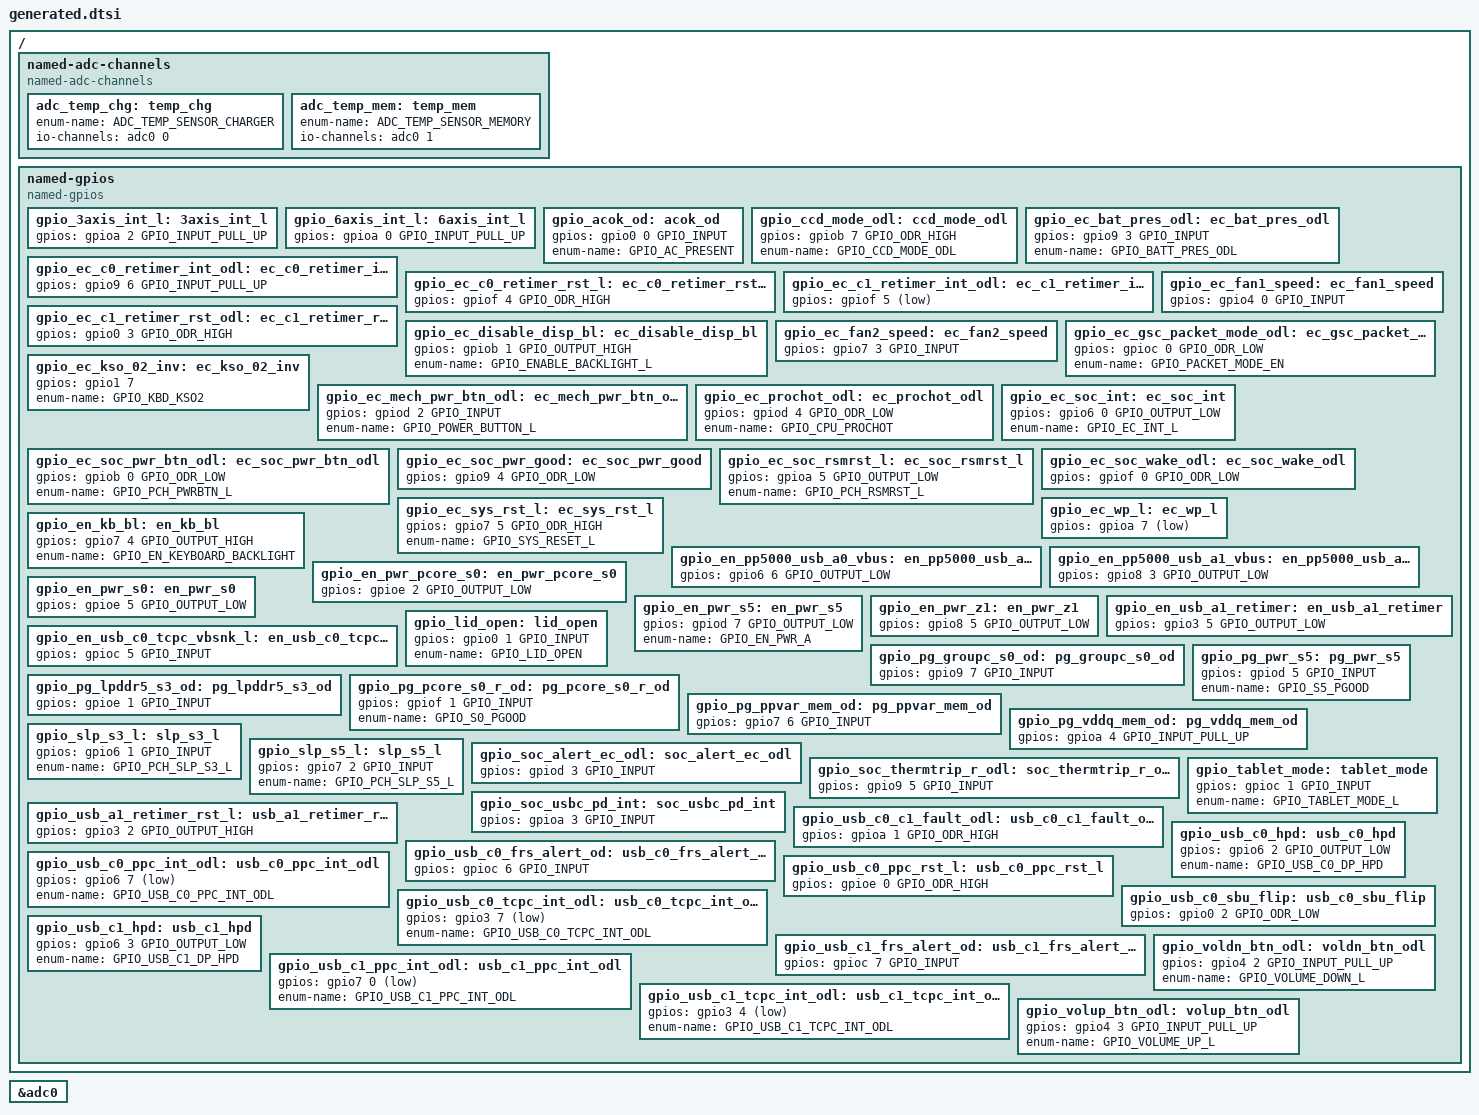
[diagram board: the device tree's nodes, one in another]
/* Copyright 2023 The ChromiumOS Authors
 * Use of this source code is governed by a BSD-style license that can be
 * found in the LICENSE file.
 *
 * This file is auto-generated - do not edit!
 */

/ {

	named-adc-channels {
		compatible = "named-adc-channels";

		adc_temp_chg: temp_chg {
			enum-name = "ADC_TEMP_SENSOR_CHARGER";
			io-channels = <&adc0 0>;
		};
		adc_temp_mem: temp_mem {
			enum-name = "ADC_TEMP_SENSOR_MEMORY";
			io-channels = <&adc0 1>;
		};
	};

	named-gpios {
		compatible = "named-gpios";

		gpio_3axis_int_l: 3axis_int_l {
			gpios = <&gpioa 2 GPIO_INPUT_PULL_UP>;
		};
		gpio_6axis_int_l: 6axis_int_l {
			gpios = <&gpioa 0 GPIO_INPUT_PULL_UP>;
		};
		gpio_acok_od: acok_od {
			gpios = <&gpio0 0 GPIO_INPUT>;
			enum-name = "GPIO_AC_PRESENT";
		};
		gpio_ccd_mode_odl: ccd_mode_odl {
			gpios = <&gpiob 7 GPIO_ODR_HIGH>;
			enum-name = "GPIO_CCD_MODE_ODL";
		};
		gpio_ec_bat_pres_odl: ec_bat_pres_odl {
			gpios = <&gpio9 3 GPIO_INPUT>;
			enum-name = "GPIO_BATT_PRES_ODL";
		};
		gpio_ec_c0_retimer_int_odl: ec_c0_retimer_int_odl {
			gpios = <&gpio9 6 GPIO_INPUT_PULL_UP>;
		};
		gpio_ec_c0_retimer_rst_l: ec_c0_retimer_rst_l {
			gpios = <&gpiof 4 GPIO_ODR_HIGH>;
		};
		gpio_ec_c1_retimer_int_odl: ec_c1_retimer_int_odl {
			gpios = <&gpiof 5 (GPIO_INPUT | GPIO_ACTIVE_LOW)>;
		};
		gpio_ec_c1_retimer_rst_odl: ec_c1_retimer_rst_odl {
			gpios = <&gpio0 3 GPIO_ODR_HIGH>;
		};
		gpio_ec_disable_disp_bl: ec_disable_disp_bl {
			gpios = <&gpiob 1 GPIO_OUTPUT_HIGH>;
			enum-name = "GPIO_ENABLE_BACKLIGHT_L";
		};
		gpio_ec_fan1_speed: ec_fan1_speed {
			gpios = <&gpio4 0 GPIO_INPUT>;
		};
		gpio_ec_fan2_speed: ec_fan2_speed {
			gpios = <&gpio7 3 GPIO_INPUT>;
		};
		gpio_ec_gsc_packet_mode_odl: ec_gsc_packet_mode_odl {
			gpios = <&gpioc 0 GPIO_ODR_LOW>;
			enum-name = "GPIO_PACKET_MODE_EN";
		};
		gpio_ec_kso_02_inv: ec_kso_02_inv {
			gpios = <&gpio1 7 (GPIO_OUTPUT | GPIO_ACTIVE_HIGH)>;
			enum-name = "GPIO_KBD_KSO2";
		};
		gpio_ec_mech_pwr_btn_odl: ec_mech_pwr_btn_odl {
			gpios = <&gpiod 2 GPIO_INPUT>;
			enum-name = "GPIO_POWER_BUTTON_L";
		};
		gpio_ec_prochot_odl: ec_prochot_odl {
			gpios = <&gpiod 4 GPIO_ODR_LOW>;
			enum-name = "GPIO_CPU_PROCHOT";
		};
		gpio_ec_soc_int: ec_soc_int {
			gpios = <&gpio6 0 GPIO_OUTPUT_LOW>;
			enum-name = "GPIO_EC_INT_L";
		};
		gpio_ec_soc_pwr_btn_odl: ec_soc_pwr_btn_odl {
			gpios = <&gpiob 0 GPIO_ODR_LOW>;
			enum-name = "GPIO_PCH_PWRBTN_L";
		};
		gpio_ec_soc_pwr_good: ec_soc_pwr_good {
			gpios = <&gpio9 4 GPIO_ODR_LOW>;
		};
		gpio_ec_soc_rsmrst_l: ec_soc_rsmrst_l {
			gpios = <&gpioa 5 GPIO_OUTPUT_LOW>;
			enum-name = "GPIO_PCH_RSMRST_L";
		};
		gpio_ec_soc_wake_odl: ec_soc_wake_odl {
			gpios = <&gpiof 0 GPIO_ODR_LOW>;
		};
		gpio_ec_sys_rst_l: ec_sys_rst_l {
			gpios = <&gpio7 5 GPIO_ODR_HIGH>;
			enum-name = "GPIO_SYS_RESET_L";
		};
		gpio_ec_wp_l: ec_wp_l {
			gpios = <&gpioa 7 (GPIO_INPUT | GPIO_ACTIVE_LOW)>;
		};
		gpio_en_kb_bl: en_kb_bl {
			gpios = <&gpio7 4 GPIO_OUTPUT_HIGH>;
			enum-name = "GPIO_EN_KEYBOARD_BACKLIGHT";
		};
		gpio_en_pp5000_usb_a0_vbus: en_pp5000_usb_a0_vbus {
			gpios = <&gpio6 6 GPIO_OUTPUT_LOW>;
		};
		gpio_en_pp5000_usb_a1_vbus: en_pp5000_usb_a1_vbus {
			gpios = <&gpio8 3 GPIO_OUTPUT_LOW>;
		};
		gpio_en_pwr_pcore_s0: en_pwr_pcore_s0 {
			gpios = <&gpioe 2 GPIO_OUTPUT_LOW>;
		};
		gpio_en_pwr_s0: en_pwr_s0 {
			gpios = <&gpioe 5 GPIO_OUTPUT_LOW>;
		};
		gpio_en_pwr_s5: en_pwr_s5 {
			gpios = <&gpiod 7 GPIO_OUTPUT_LOW>;
			enum-name = "GPIO_EN_PWR_A";
		};
		gpio_en_pwr_z1: en_pwr_z1 {
			gpios = <&gpio8 5 GPIO_OUTPUT_LOW>;
		};
		gpio_en_usb_a1_retimer: en_usb_a1_retimer {
			gpios = <&gpio3 5 GPIO_OUTPUT_LOW>;
		};
		gpio_en_usb_c0_tcpc_vbsnk_l: en_usb_c0_tcpc_vbsnk_l {
			gpios = <&gpioc 5 GPIO_INPUT>;
		};
		gpio_lid_open: lid_open {
			gpios = <&gpio0 1 GPIO_INPUT>;
			enum-name = "GPIO_LID_OPEN";
		};
		gpio_pg_groupc_s0_od: pg_groupc_s0_od {
			gpios = <&gpio9 7 GPIO_INPUT>;
		};
		gpio_pg_lpddr5_s3_od: pg_lpddr5_s3_od {
			gpios = <&gpioe 1 GPIO_INPUT>;
		};
		gpio_pg_pcore_s0_r_od: pg_pcore_s0_r_od {
			gpios = <&gpiof 1 GPIO_INPUT>;
			enum-name = "GPIO_S0_PGOOD";
		};
		gpio_pg_ppvar_mem_od: pg_ppvar_mem_od {
			gpios = <&gpio7 6 GPIO_INPUT>;
		};
		gpio_pg_pwr_s5: pg_pwr_s5 {
			gpios = <&gpiod 5 GPIO_INPUT>;
			enum-name = "GPIO_S5_PGOOD";
		};
		gpio_pg_vddq_mem_od: pg_vddq_mem_od {
			gpios = <&gpioa 4 GPIO_INPUT_PULL_UP>;
		};
		gpio_slp_s3_l: slp_s3_l {
			gpios = <&gpio6 1 GPIO_INPUT>;
			enum-name = "GPIO_PCH_SLP_S3_L";
		};
		gpio_slp_s5_l: slp_s5_l {
			gpios = <&gpio7 2 GPIO_INPUT>;
			enum-name = "GPIO_PCH_SLP_S5_L";
		};
		gpio_soc_alert_ec_odl: soc_alert_ec_odl {
			gpios = <&gpiod 3 GPIO_INPUT>;
		};
		gpio_soc_thermtrip_r_odl: soc_thermtrip_r_odl {
			gpios = <&gpio9 5 GPIO_INPUT>;
		};
		gpio_soc_usbc_pd_int: soc_usbc_pd_int {
			gpios = <&gpioa 3 GPIO_INPUT>;
		};
		gpio_tablet_mode: tablet_mode {
			gpios = <&gpioc 1 GPIO_INPUT>;
			enum-name = "GPIO_TABLET_MODE_L";
		};
		gpio_usb_a1_retimer_rst_l: usb_a1_retimer_rst_l {
			gpios = <&gpio3 2 GPIO_OUTPUT_HIGH>;
		};
		gpio_usb_c0_c1_fault_odl: usb_c0_c1_fault_odl {
			gpios = <&gpioa 1 GPIO_ODR_HIGH>;
		};
		gpio_usb_c0_frs_alert_od: usb_c0_frs_alert_od {
			gpios = <&gpioc 6 GPIO_INPUT>;
		};
		gpio_usb_c0_hpd: usb_c0_hpd {
			gpios = <&gpio6 2 GPIO_OUTPUT_LOW>;
			enum-name = "GPIO_USB_C0_DP_HPD";
		};
		gpio_usb_c0_ppc_int_odl: usb_c0_ppc_int_odl {
			gpios = <&gpio6 7 (GPIO_INPUT_PULL_UP | GPIO_ACTIVE_LOW)>;
			enum-name = "GPIO_USB_C0_PPC_INT_ODL";
		};
		gpio_usb_c0_ppc_rst_l: usb_c0_ppc_rst_l {
			gpios = <&gpioe 0 GPIO_ODR_HIGH>;
		};
		gpio_usb_c0_sbu_flip: usb_c0_sbu_flip {
			gpios = <&gpio0 2 GPIO_ODR_LOW>;
		};
		gpio_usb_c0_tcpc_int_odl: usb_c0_tcpc_int_odl {
			gpios = <&gpio3 7 (GPIO_INPUT | GPIO_ACTIVE_LOW)>;
			enum-name = "GPIO_USB_C0_TCPC_INT_ODL";
		};
		gpio_usb_c1_frs_alert_od: usb_c1_frs_alert_od {
			gpios = <&gpioc 7 GPIO_INPUT>;
		};
		gpio_usb_c1_hpd: usb_c1_hpd {
			gpios = <&gpio6 3 GPIO_OUTPUT_LOW>;
			enum-name = "GPIO_USB_C1_DP_HPD";
		};
		gpio_usb_c1_ppc_int_odl: usb_c1_ppc_int_odl {
			gpios = <&gpio7 0 (GPIO_INPUT | GPIO_ACTIVE_LOW)>;
			enum-name = "GPIO_USB_C1_PPC_INT_ODL";
		};
		gpio_usb_c1_tcpc_int_odl: usb_c1_tcpc_int_odl {
			gpios = <&gpio3 4 (GPIO_INPUT | GPIO_ACTIVE_LOW)>;
			enum-name = "GPIO_USB_C1_TCPC_INT_ODL";
		};
		gpio_voldn_btn_odl: voldn_btn_odl {
			gpios = <&gpio4 2 GPIO_INPUT_PULL_UP>;
			enum-name = "GPIO_VOLUME_DOWN_L";
		};
		gpio_volup_btn_odl: volup_btn_odl {
			gpios = <&gpio4 3 GPIO_INPUT_PULL_UP>;
			enum-name = "GPIO_VOLUME_UP_L";
		};
	};
};

&adc0 {
	status = "okay";
};
